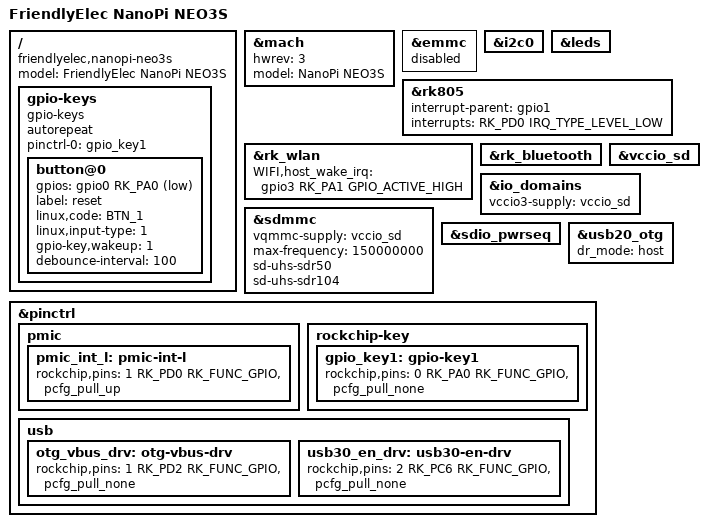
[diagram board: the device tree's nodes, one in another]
/*
 * Copyright (c) 2019 FriendlyElec Computer Tech. Co., Ltd.
 * (http://www.friendlyarm.com)
 *
 * This program is free software; you can redistribute it and/or
 * modify it under the terms of the GNU General Public License
 * as published by the Free Software Foundation; either version 2
 * of the License, or (at your option) any later version.
 *
 * This program is distributed in the hope that it will be useful,
 * but WITHOUT ANY WARRANTY; without even the implied warranty of
 * MERCHANTABILITY or FITNESS FOR A PARTICULAR PURPOSE.  See the
 * GNU General Public License for more details.
 *
 * You should have received a copy of the GNU General Public License
 * along with this program.  If not, see <http://www.gnu.org/licenses/>.
 */

/dts-v1/;
#include "rk3328-nanopi-r2-common.dtsi"

/ {
	model = "FriendlyElec NanoPi NEO3S";
	compatible = "friendlyelec,nanopi-neo3s", "rockchip,rk3328";

	gpio-keys {
		compatible = "gpio-keys";
		#address-cells = <1>;
		#size-cells = <0>;
		autorepeat;

		pinctrl-names = "default";
		pinctrl-0 = <&gpio_key1>;

		button@0 {
			gpios = <&gpio0 RK_PA0 GPIO_ACTIVE_LOW>;
			label = "reset";
			linux,code = <BTN_1>;
			linux,input-type = <1>;
			gpio-key,wakeup = <1>;
			debounce-interval = <100>;
		};
	};
};

&mach {
	hwrev = <3>;
	model = "NanoPi NEO3S";
};

&emmc {
	status = "disabled";
};

&i2c0 {
	status = "okay";
};

&leds {
	status = "okay";
};

&rk805 {
	interrupt-parent = <&gpio1>;
	interrupts = <RK_PD0 IRQ_TYPE_LEVEL_LOW>;
};

&rk_wlan {
	status = "okay";
	WIFI,host_wake_irq = <&gpio3 RK_PA1 GPIO_ACTIVE_HIGH>;
};

&rk_bluetooth {
	status = "okay";
};

&vccio_sd {
	status = "okay";
};

&io_domains {
	vccio3-supply = <&vccio_sd>;
};

&sdmmc {
	vqmmc-supply = <&vccio_sd>;
	max-frequency = <150000000>;
	sd-uhs-sdr50;
	sd-uhs-sdr104;
	status = "okay";
};

&sdio_pwrseq {
	status = "okay";
};

&usb20_otg {
	dr_mode = "host";
	status = "okay";
};

&pinctrl {
	pmic {
		pmic_int_l: pmic-int-l {
			rockchip,pins = <1 RK_PD0 RK_FUNC_GPIO &pcfg_pull_up>;
		};
	};

	rockchip-key {
		gpio_key1: gpio-key1 {
			rockchip,pins = <0 RK_PA0 RK_FUNC_GPIO &pcfg_pull_none>;
		};
	};

	usb {
		otg_vbus_drv: otg-vbus-drv {
			rockchip,pins = <1 RK_PD2 RK_FUNC_GPIO &pcfg_pull_none>;
		};

		usb30_en_drv: usb30-en-drv {
			rockchip,pins = <2 RK_PC6 RK_FUNC_GPIO &pcfg_pull_none>;
		};
	};
};
